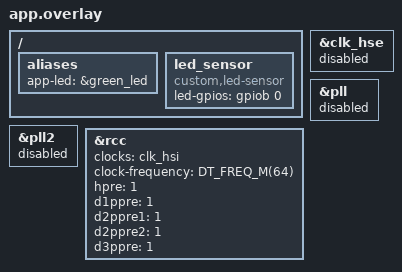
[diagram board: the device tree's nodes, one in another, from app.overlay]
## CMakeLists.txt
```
cmake_minimum_required(VERSION 3.20.0)
list(APPEND ZEPHYR_EXTRA_MODULES ${CMAKE_CURRENT_SOURCE_DIR}/modules/led_sensor)

find_package(Zephyr REQUIRED)
project(my_zephyr_app)

target_sources(app PRIVATE src/main.cpp)
target_sources(app PRIVATE src/main.cpp src/sensor_shell.c)
```

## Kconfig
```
source "Kconfig.zephyr"

config APP_HEARTBEAT_PERIOD_MS
int "Heartbeat period (ms)"
default 500
range 100 2000

menuconfig LED_SUBSYSTEM
    bool "LED Subsystem"
    default y

if LED_SUBSYSTEM

choice LED_BLINK_SLEEP_CHOICE
    prompt "LED blink sleep time"
    default LED_BLINK_SLEEP_1S

config LED_BLINK_SLEEP_250MS
    bool "250ms"

config LED_BLINK_SLEEP_500MS
    bool "500ms"

config LED_BLINK_SLEEP_1S
    bool "1s (medium)"

config LED_BLINK_SLEEP_2S
    bool "2s"

endchoice

# Hidden integer containing the actual sleep time in milliseconds.
config LED_BLINK_SLEEP_TIME_MS
    int
    default 250 if LED_BLINK_SLEEP_250MS
    default 500 if LED_BLINK_SLEEP_500MS
    default 1000 if LED_BLINK_SLEEP_1S
    default 2000 if LED_BLINK_SLEEP_2S


menuconfig LED_ADVANCED
    bool "Advanced LED settings"
    default n

if LED_ADVANCED

config LED_BRIGHTNESS
    int "LED brightness (0-100)"
    default 100
    range 0 100

config LED_FADE_DURATION_MS
    int "LED fade duration (ms)"
    default 500
    range 0 5000

menu "Expert settings"
    visible if LED_ADVANCED

config LED_DEBUGGING
    bool "Enable LED debugging"
    default n

config LED_CUSTOM_BLINK
    bool "Custom blink pattern"
    default n

endmenu

endif # LED_ADVANCED

endif # LED_SUBSYSTEM
```

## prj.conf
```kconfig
CONFIG_GPIO=y
CONFIG_LOG=y

CONFIG_LED_SUBSYSTEM=y

CONFIG_LED_BLINK_SLEEP_1S=y
CONFIG_APP_HEARTBEAT_PERIOD_MS=300

CONFIG_LED_ADVANCED=n
CONFIG_LED_BRIGHTNESS=50
CONFIG_LED_FADE_DURATION_MS=400

CONFIG_LED_DEBUGGING=n
CONFIG_LED_CUSTOM_BLINK=n

CONFIG_SENSOR=y

CONFIG_SHELL=y
```

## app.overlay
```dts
/ {
	aliases {
		app-led = &green_led;
	};

	led_sensor: led_sensor {
		compatible = "custom,led-sensor";
		led-gpios = <&gpiob 0 GPIO_ACTIVE_HIGH>;
		status = "okay";
	};
};

&clk_hse {
	status = "disabled";
};

&pll {
	status = "disabled";
};

&pll2 {
	status = "disabled";
};

&rcc {
	clocks = <&clk_hsi>;
	clock-frequency = <DT_FREQ_M(64)>;
	hpre = <1>;
	d1ppre = <1>;
	d2ppre1 = <1>;
	d2ppre2 = <1>;
	d3ppre = <1>;
};
```

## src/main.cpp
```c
#include <zephyr/kernel.h>
#include <zephyr/device.h>
#include <zephyr/sys/printk.h>

int main()
{
    const struct device *dev = DEVICE_DT_GET_ANY(custom_led_sensor);

    if (dev == NULL || !device_is_ready(dev)) {
        printk("LED sensor not ready\n");
        return 0;
    }

    printk("LED sensor ready. Try: sensor info\n");
    return 0;
}
```

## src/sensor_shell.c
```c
#include <zephyr/device.h>
#include <zephyr/drivers/sensor.h>
#include <zephyr/shell/shell.h>
#include <led_sensor/led_sensor.h>


static const struct device *const led_dev = DEVICE_DT_GET_ANY(custom_led_sensor);

static int cmd_sensor_fetch(const struct shell *sh, size_t argc, char **argv)
{
	ARG_UNUSED(argc);
	ARG_UNUSED(argv);

	if (!device_is_ready(led_dev)) {
		shell_error(sh, "Device %s not ready", led_dev->name);
		return -ENODEV;
	}

	int ret = sensor_sample_fetch(led_dev);

	if (ret < 0) {
		shell_error(sh, "sensor_sample_fetch failed: %d", ret);
		return ret;
	}

	shell_print(sh, "Sample fetched (LED on)");
	return 0;
}

static int cmd_sensor_read(const struct shell *sh, size_t argc, char **argv)
{
	ARG_UNUSED(argc);
	ARG_UNUSED(argv);

	struct sensor_value val;

	if (!device_is_ready(led_dev)) {
		shell_error(sh, "Device %s not ready", led_dev->name);
		return -ENODEV;
	}

	int ret = sensor_channel_get(led_dev, SENSOR_CHAN_ALL, &val);

	if (ret < 0) {
		shell_error(sh, "sensor_channel_get failed: %d", ret);
		return ret;
	}

	shell_print(sh, "Value: %d.%06d (LED was %s, now off)", val.val1, val.val2,
		    val.val1 ? "on" : "off");
	return 0;
}

static int cmd_sensor_info(const struct shell *sh, size_t argc, char **argv)
{
	ARG_UNUSED(argc);
	ARG_UNUSED(argv);

	shell_print(sh, "Device: %s", led_dev->name);
	shell_print(sh, "Ready:  %s", device_is_ready(led_dev) ? "yes" : "no");
	return 0;
}

static int cmd_sensor_set(const struct shell *sh, size_t argc, char **argv)
{
	int err = 0;
	long value;

	if (argc < 2) {
		shell_error(sh, "Missing value. Usage: sensor set <0|1>");
		return -EINVAL;
	}

	value = shell_strtol(argv[1], 10, &err);
	if (err != 0) {
		shell_error(sh, "Invalid number: %s", argv[1]);
		return -EINVAL;
	}

	if (value < 0 || value > 1) {
		shell_error(sh, "Value out of range: %ld (allowed: 0 or 1)", value);
		return -EINVAL;
	}

	if (!device_is_ready(led_dev)) {
		shell_error(sh, "Device %s not ready", led_dev->name);
		return -ENODEV;
	}

	int ret = led_sensor_set_enabled(led_dev, value == 1);

	if (ret < 0) {
		shell_error(sh, "led_sensor_set_enabled failed: %d", ret);
		return ret;
	}

	shell_print(sh, "LED sensor %s", value ? "enabled" : "disabled");
	return 0;
}


SHELL_STATIC_SUBCMD_SET_CREATE(sub_sensor,
	SHELL_CMD(fetch, NULL, "Fetch a sample (turns LED on)", cmd_sensor_fetch),
	SHELL_CMD(read, NULL, "Read and print the value (turns LED off)", cmd_sensor_read),
	SHELL_CMD(info, NULL, "Print device name and ready state", cmd_sensor_info),
	SHELL_CMD_ARG(set, NULL, "Enable (1) or disable (0) the LED sensor: set <0|1>",
		      cmd_sensor_set, 1, 1),
	SHELL_SUBCMD_SET_END
);


SHELL_CMD_REGISTER(sensor, &sub_sensor, "LED sensor commands", NULL);
```
